AUTOSAR XML (schema 314)
package /ComponentType
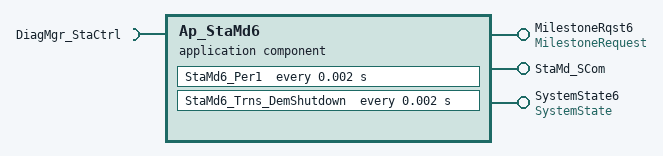
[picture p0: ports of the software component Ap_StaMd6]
  application software component type Ap_StaMd6
    provide port MilestoneRqst6: provided-interface=MilestoneRequest
      provided-com-specs:
        operation=WarmInitMilestoneComplete, queue-length=1
        operation=WarmInitMilestoneNotComplete, queue-length=1
    provide port StaMd_SCom: provided-com-specs=[{operation=EcuReset, queue-length=1}, {operation=FBLTransitionReq, queue-length=1}], provided-interface=StaMd_SCom
    provide port SystemState6: mode-switch-com-spec{mode-group=Mode, queue-length=1}, provided-interface=SystemState
    require port DiagMgr_StaCtrl: client-com-spec=Shutdown, required-interface=DiagMgr_StaCtrl
  internal behavior Ap_StaMd6_InternalBehavior: component=Ap_StaMd6
    4 x operation invoked event:
      OIT_MilestoneRqst6_WarmInitMilestoneComplete_MilestoneRqst6_WarmInitMilestoneComplete: start-on-event=MilestoneRqst6_WarmInitMilestoneComplete, operation=MilestoneRqst6.WarmInitMilestoneComplete
      OIT_MilestoneRqst6_WarmInitMilestoneNotComplete_MilestoneRqst6_WarmInitMilestoneNotComplete: start-on-event=MilestoneRqst6_WarmInitMilestoneNotComplete, operation=MilestoneRqst6.WarmInitMilestoneNotComplete
      OIT_StaMd_SCom_EcuReset_StaMd_SCom_EcuReset: start-on-event=StaMd_SCom_EcuReset, operation=StaMd_SCom.EcuReset
      OIT_StaMd_SCom_FBLTransitionReq_StaMd_SCom_FBLTransitionReq: start-on-event=StaMd_SCom_FBLTransitionReq, operation=StaMd_SCom.FBLTransitionReq
    timing event TMT_StaMd6_Per1: start-on-event=StaMd6_Per1, period=0.002
    timing event TMT_StaMd6_Trns_DemShutdown: start-on-event=StaMd6_Trns_DemShutdown, period=0.002
    exclusive area StaMds6_MilestoneRqst_WARMINIT_ExclArea
    port-api-options:
      enable-take-address=false, indirect-api=false, port=DiagMgr_StaCtrl
      enable-take-address=false, indirect-api=false, port=MilestoneRqst6
      enable-take-address=false, indirect-api=false, port=StaMd_SCom
      enable-take-address=false, indirect-api=false, port=SystemState6
    6 x runnable:
      MilestoneRqst6_WarmInitMilestoneComplete: can-be-invoked-concurrently=true, can-enter-exclusive-area=StaMds6_MilestoneRqst_WARMINIT_ExclArea
      MilestoneRqst6_WarmInitMilestoneNotComplete: can-be-invoked-concurrently=true, can-enter-exclusive-area=StaMds6_MilestoneRqst_WARMINIT_ExclArea
      StaMd_SCom_EcuReset
      StaMd_SCom_FBLTransitionReq
      StaMd6_Per1
        mode switch point SWITCH_SystemState6_Mode: mode-group=SystemState6.Mode
      StaMd6_Trns_DemShutdown
        sync call SC_DiagMgr_StaCtrl_Shutdown: operation=DiagMgr_StaCtrl.Shutdown, timeout=0
  swc implementation Ap_StaMd6_Implementation: behavior=Ap_StaMd6_InternalBehavior
    code-descriptors:
      code Code: type=SRC
